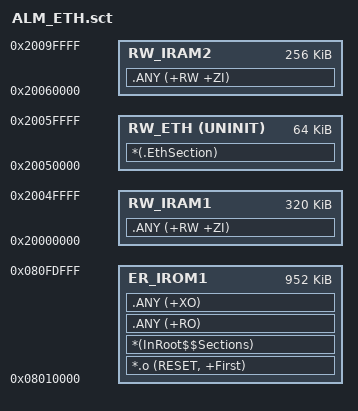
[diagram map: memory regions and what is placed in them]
; *************************************************************
; *** Scatter-Loading Description File generated by uVision ***
; *************************************************************

LR_IROM1 0x08010000 0x000EE000  {    ; App: 64KB offset, 952KB size (ALM_ETH_Bootloader at 0x08000000-0x0800FFFF)
  ER_IROM1 0x08010000 0x000EE000  {  ; load address = execution address
   *.o (RESET, +First)
   *(InRoot$$Sections)
   .ANY (+RO)
   .ANY (+XO)
  }
  RW_IRAM1 0x20000000 0x00050000  {  ; SRAM1+SRAM2 (cacheable)
   .ANY (+RW +ZI)
  }
  RW_ETH 0x20050000 UNINIT 0x00010000  {  ; SRAM3 64KB (non-cacheable via MPU)
   *(.EthSection)
  }
  RW_IRAM2 0x20060000 0x00040000  {  ; remaining SRAM3 (cacheable)
   .ANY (+RW +ZI)
  }
}
